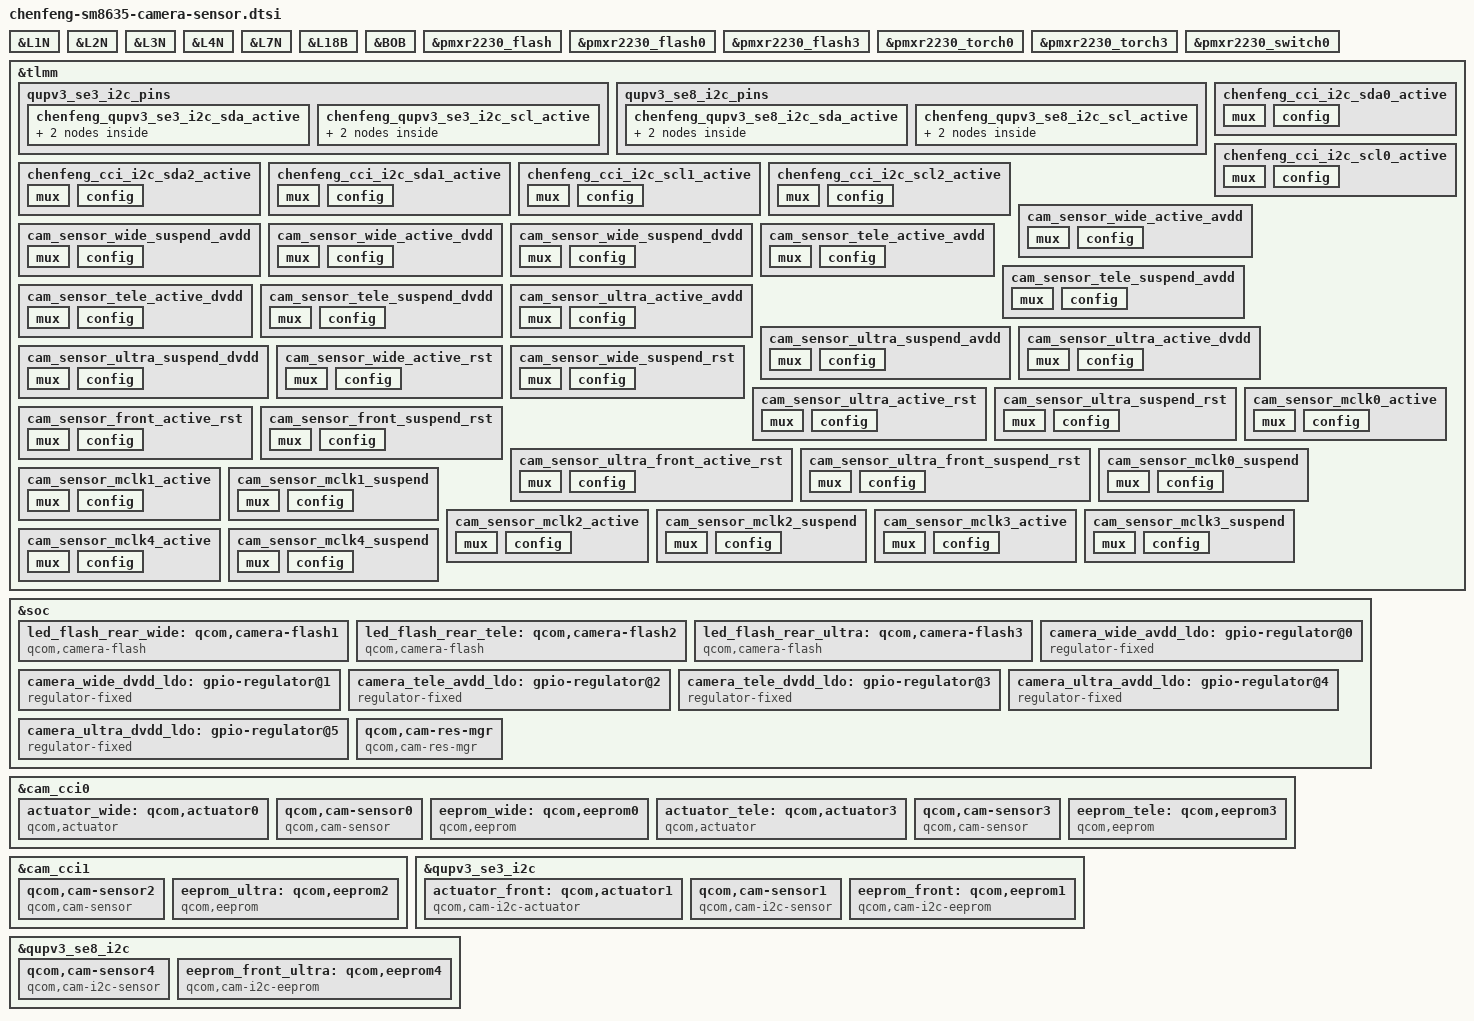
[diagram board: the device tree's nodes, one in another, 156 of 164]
#include <dt-bindings/msm-camera.h>

&L1N {
	regulator-min-microvolt = <1000000>;
	regulator-max-microvolt = <1000000>;
	qcom,init-voltage = <1000000>;
};

&L2N {
	regulator-min-microvolt = <1000000>;
	regulator-max-microvolt = <1000000>;
	qcom,init-voltage = <1000000>;
};

&L3N {
	regulator-min-microvolt = <2800000>;
	regulator-max-microvolt = <2800000>;
	qcom,init-voltage = <2800000>;
};

// CAM2X_AF_2P8
&L4N {
	regulator-min-microvolt = <2800000>;
	regulator-max-microvolt = <2800000>;
	qcom,init-voltage = <2800000>;
};

// CAMW_AFVDD_3P1
&L7N {
	regulator-min-microvolt = <3100000>;
	regulator-max-microvolt = <3100000>;
	qcom,init-voltage = <3100000>;
};

// CAMF_AFVDD_2P8
&L18B {
	regulator-min-microvolt = <2800000>;
	regulator-max-microvolt = <2800000>;
	qcom,init-voltage = <2800000>;
};

&BOB {
	regulator-min-microvolt = <3008000>;
	regulator-max-microvolt = <3960000>;
};

&pmxr2230_flash {
	status = "ok";
};

&pmxr2230_flash0 {
	qcom,max-current-ma = <400>;
	qcom,duration-ms = <300>;
	xiaomi,max-duration-ms = <300>;
};

&pmxr2230_flash3 {
	qcom,max-current-ma = <400>;
	qcom,duration-ms = <300>;
	xiaomi,max-duration-ms = <300>;
};

&pmxr2230_torch0{
	qcom,max-current-ma = <425>;
	xiaomi,currents-with-time = <425 150>;
	xiaomi,time-for-currents = <5000 0xFFFFFFFF>;  /* 0xFFFFFFFF means flash always on*/
};

&pmxr2230_torch3{
	qcom,max-current-ma = <425>;
	xiaomi,currents-with-time = <425 150>;
	xiaomi,time-for-currents = <5000 0xFFFFFFFF>;  /* 0xFFFFFFFF means flash always on*/
};

&pmxr2230_switch0 {
	qcom,led-mask = <9>; /* Channels 1 & 4 */
	qcom,symmetry-en;
};

&tlmm {

	qupv3_se3_i2c_pins: qupv3_se3_i2c_pins {
		chenfeng_qupv3_se3_i2c_sda_active: chenfeng_qupv3_se3_i2c_sda_active {
			mux {
				pins = "gpio12";
				function = "qup0_se3_l0";
			};

			config {
				pins = "gpio12";
				drive-strength = <2>;
				bias-disable; /* NO PULL */
				qcom,apps;
			};
		};

		chenfeng_qupv3_se3_i2c_scl_active: chenfeng_qupv3_se3_i2c_scl_active {
			mux {
				pins = "gpio13";
				function = "qup0_se3_l1";
			};

			config {
				pins = "gpio13";
				drive-strength = <2>;
				bias-disable; /* NO PULL */
				qcom,apps;
			};
		};
	};

	qupv3_se8_i2c_pins: qupv3_se8_i2c_pins {
		chenfeng_qupv3_se8_i2c_sda_active: chenfeng_qupv3_se8_i2c_sda_active {
			mux {
				pins = "gpio0";
				function = "qup1_se0_l0";
			};

			config {
				pins = "gpio0";
				drive-strength = <2>;
				bias-disable; /* NO PULL */
				qcom,apps;
			};
		};

		chenfeng_qupv3_se8_i2c_scl_active: chenfeng_qupv3_se8_i2c_scl_active {
			mux {
				pins = "gpio1";
				function = "qup1_se0_l1";
			};

			config {
				pins = "gpio1";
				drive-strength = <2>;
				bias-disable; /* NO PULL */
				qcom,apps;
			};
		};
	};

	chenfeng_cci_i2c_sda0_active: chenfeng_cci_i2c_sda0_active {
		mux {
			/* CLK, DATA */
			pins = "gpio70";
			function = "cci_i2c_sda0";
		};

		config {
			pins = "gpio70";
			bias-disable; /* NO PULL */
			drive-strength = <2>; /* 2 MA */
		};
	};

	chenfeng_cci_i2c_scl0_active: chenfeng_cci_i2c_scl0_active {
		mux {
			/* CLK, DATA */
			pins = "gpio71";
			function = "cci_i2c_scl0";
		};

		config {
			pins = "gpio71";
			bias-disable; /* NO PULL */
			drive-strength = <2>; /* 2 MA */
		};
	};

	chenfeng_cci_i2c_sda2_active: chenfeng_cci_i2c_sda2_active {
		mux {
			/* CLK, DATA */
			pins = "gpio74";
			function = "cci_i2c_sda2";
		};

		config {
			pins = "gpio74";
			bias-disable; /* NO PULL */
			drive-strength = <2>; /* 2 MA */
		};
	};

	chenfeng_cci_i2c_sda1_active: chenfeng_cci_i2c_sda1_active {
		mux {
			/* CLK, DATA */
			pins = "gpio72";
			function = "cci_i2c_sda1";
		};

		config {
			pins = "gpio72";
			bias-disable; /* NO PULL */
			drive-strength = <2>; /* 2 MA */
		};
	};

	chenfeng_cci_i2c_scl1_active: chenfeng_cci_i2c_scl1_active {
		mux {
			/* CLK, DATA */
			pins = "gpio73";
			function = "cci_i2c_scl1";
		};

		config {
			pins = "gpio73";
			bias-disable; /* NO PULL */
			drive-strength = <2>; /* 2 MA */
		};
	};

	chenfeng_cci_i2c_scl2_active: chenfeng_cci_i2c_scl2_active {
		mux {
			/* CLK, DATA */
			pins = "gpio75";
			function = "cci_i2c_scl2";
		};

		config {
			pins = "gpio75";
			bias-disable; /* NO PULL */
			drive-strength = <2>; /* 2 MA */
		};
	};


//WIDE avdd
	cam_sensor_wide_active_avdd: cam_sensor_wide_active_avdd {
		mux {
			pins = "gpio34";
			function = "gpio";
		};
		config {
			pins = "gpio34";
			bias-disable; /* No PULL */
			drive-strength = <2>; /* 2 MA */
		};
	};
	cam_sensor_wide_suspend_avdd: cam_sensor_wide_suspend_avdd {
		mux {
			pins = "gpio34";
			function = "gpio";
		};
		config {
			pins = "gpio34";
			bias-pull-down; /* PULL DOWN */
			drive-strength = <2>; /* 2 MA */
			output-low;
		};
	};

//WIDE dvdd
	cam_sensor_wide_active_dvdd: cam_sensor_wide_active_dvdd {
		mux {
			pins = "gpio116";
			function = "gpio";
		};
		config {
			pins = "gpio116";
			bias-disable; /* No PULL */
			drive-strength = <2>; /* 2 MA */
		};
	};
	cam_sensor_wide_suspend_dvdd: cam_sensor_wide_suspend_dvdd {
		mux {
			pins = "gpio116";
			function = "gpio";
		};
		config {
			pins = "gpio116";
			bias-pull-down; /* PULL DOWN */
			drive-strength = <2>; /* 2 MA */
			output-low;
		};
	};

//tele avdd
	cam_sensor_tele_active_avdd: cam_sensor_tele_active_avdd {
		mux {
			pins = "gpio149";
			function = "gpio";
		};

		config {
			pins = "gpio149";
			bias-disable; /* No PULL */
			drive-strength = <2>; /* 2 MA */
		};
	};
	cam_sensor_tele_suspend_avdd: cam_sensor_tele_suspend_avdd {
		mux {
			pins = "gpio149";
			function = "gpio";
		};

		config {
			pins = "gpio149";
			bias-pull-down; /* PULL DOWN */
			drive-strength = <2>; /* 2 MA */
			output-low;
		};
	};

//tele dvdd
	cam_sensor_tele_active_dvdd: cam_sensor_tele_active_dvdd {
		mux {
			pins = "gpio153";
			function = "gpio";
		};

		config {
			pins = "gpio153";
			bias-disable; /* No PULL */
			drive-strength = <2>; /* 2 MA */
		};
	};
	cam_sensor_tele_suspend_dvdd: cam_sensor_tele_suspend_dvdd {
		mux {
			pins = "gpio153";
			function = "gpio";
		};

		config {
			pins = "gpio153";
			bias-pull-down; /* PULL DOWN */
			drive-strength = <2>; /* 2 MA */
			output-low;
		};
	};

//ultra avdd
	cam_sensor_ultra_active_avdd: cam_sensor_ultra_active_avdd {
		mux {
			pins = "gpio123";
			function = "gpio";
		};
		config {
			pins = "gpio123";
			bias-disable; /* No PULL */
			drive-strength = <2>; /* 2 MA */
		};
	};
	cam_sensor_ultra_suspend_avdd: cam_sensor_ultra_suspend_avdd {
		mux {
			pins = "gpio123";
			function = "gpio";
		};
		config {
			pins = "gpio123";
			bias-pull-down; /* PULL DOWN */
			drive-strength = <2>; /* 2 MA */
			output-low;
		};
	};

//ultra dvdd
	cam_sensor_ultra_active_dvdd: cam_sensor_ultra_active_dvdd {
		mux {
			pins = "gpio124";
			function = "gpio";
		};
		config {
			pins = "gpio124";
			bias-disable; /* No PULL */
			drive-strength = <2>; /* 2 MA */
		};
	};
	cam_sensor_ultra_suspend_dvdd: cam_sensor_ultra_suspend_dvdd {
		mux {
			pins = "gpio124";
			function = "gpio";
		};
		config {
			pins = "gpio124";
			bias-pull-down; /* PULL DOWN */
			drive-strength = <2>; /* 2 MA */
			output-low;
		};
	};

// wide rst
	cam_sensor_wide_active_rst: cam_sensor_wide_active_rst {
		mux {
			pins = "gpio15";
			function = "gpio";
		};

		config {
			pins = "gpio15";
			bias-disable; /* No PULL */
			drive-strength = <2>; /* 2 MA */
		};
	};
	cam_sensor_wide_suspend_rst: cam_sensor_wide_suspend_rst {
		mux {
			pins = "gpio15";
			function = "gpio";
		};

		config {
			pins = "gpio15";
			bias-pull-down; /* PULL DOWN */
			drive-strength = <2>; /* 2 MA */
			output-low;
		};
	};

// ultra rst
	cam_sensor_ultra_active_rst: cam_sensor_ultra_active_rst {
		mux {
			pins = "gpio20";
			function = "gpio";
		};

		config {
			pins = "gpio20";
			bias-disable; /* No PULL */
			drive-strength = <2>; /* 2 MA */
		};
	};
	cam_sensor_ultra_suspend_rst: cam_sensor_ultra_suspend_rst {
		mux {
			pins = "gpio20";
			function = "gpio";
		};

		config {
			pins = "gpio20";
			bias-pull-down; /* PULL DOWN */
			drive-strength = <2>; /* 2 MA */
			output-low;
		};
	};

// front rst
	cam_sensor_front_active_rst: cam_sensor_front_active_rst {
		mux {
			pins = "gpio21";
			function = "gpio";
		};

		config {
			pins = "gpio21";
			bias-disable; /* No PULL */
			drive-strength = <2>; /* 2 MA */
		};
	};
	cam_sensor_front_suspend_rst: cam_sensor_front_suspend_rst {
		mux {
			pins = "gpio21";
			function = "gpio";
		};

		config {
			pins = "gpio21";
			bias-pull-down; /* PULL DOWN */
			drive-strength = <2>; /* 2 MA */
			output-low;
		};
	};

// ultra front rst
	cam_sensor_ultra_front_active_rst: cam_sensor_ultra_front_active_rst {
		mux {
			pins = "gpio3";
			function = "gpio";
		};
		config {
			pins = "gpio3";
			bias-disable; /* No PULL */
			drive-strength = <2>; /* 2 MA */
			qcom,apps;
		};
	};
	cam_sensor_ultra_front_suspend_rst: cam_sensor_ultra_front_suspend_rst {
		mux {
			pins = "gpio3";
			function = "gpio";
		};
		config {
			pins = "gpio3";
			bias-pull-down; /* PULL DOWN */
			drive-strength = <2>; /* 2 MA */
			output-low;
			qcom,remote;
		};
	};

// wide mclk
	cam_sensor_mclk0_active: cam_sensor_mclk0_active {
		/* MCLK0 */
		mux {
			pins = "gpio64";
			function = "cam_mclk";
		};

		config {
			pins = "gpio64";
			bias-disable; /* No PULL */
			drive-strength = <4>; /* 4 MA */
		};
	};

	cam_sensor_mclk0_suspend: cam_sensor_mclk0_suspend {
		/* MCLK0 */
		mux {
			pins = "gpio64";
			function = "cam_mclk";
		};

		config {
			pins = "gpio64";
			bias-pull-down; /* PULL DOWN */
			drive-strength = <4>; /* 4 MA */
		};
	};

// tele mclk
	cam_sensor_mclk1_active: cam_sensor_mclk1_active {
		/* MCLK1 */
		mux {
			pins = "gpio65";
			function = "cam_mclk";
		};

		config {
			pins = "gpio65";
			bias-disable; /* No PULL */
			drive-strength = <4>; /* 4 MA */
		};
	};

	cam_sensor_mclk1_suspend: cam_sensor_mclk1_suspend {
		/* MCLK1 */
		mux {
			pins = "gpio65";
			function = "cam_mclk";
		};

		config {
			pins = "gpio65";
			bias-pull-down; /* PULL DOWN */
			drive-strength = <4>; /* 4 MA */
		};
	};

// ultra mclk
	cam_sensor_mclk2_active: cam_sensor_mclk2_active {
		/* MCLK2 */
		mux {
			pins = "gpio66";
			function = "cam_mclk";
		};

		config {
			pins = "gpio66";
			bias-disable; /* No PULL */
			drive-strength = <4>; /* 4 MA */
		};
	};

	cam_sensor_mclk2_suspend: cam_sensor_mclk2_suspend {
		/* MCLK2 */
		mux {
			pins = "gpio66";
			function = "cam_mclk";
		};

		config {
			pins = "gpio66";
			bias-pull-down; /* PULL DOWN */
			drive-strength = <4>; /* 4 MA */
		};
	};

// front mclk
	cam_sensor_mclk3_active: cam_sensor_mclk3_active {
		/* MCLK3 */
		mux {
			pins = "gpio67";
			function = "cam_mclk";
		};

		config {
			pins = "gpio67";
			bias-disable; /* No PULL */
			drive-strength = <4>; /* 4 MA */
		};
	};

	cam_sensor_mclk3_suspend: cam_sensor_mclk3_suspend {
		/* MCLK3 */
		mux {
			pins = "gpio67";
			function = "cam_mclk";
		};

		config {
			pins = "gpio67";
			bias-pull-down; /* PULL DOWN */
			drive-strength = <4>; /* 4 MA */
		};
	};

// front ultra
	cam_sensor_mclk4_active: cam_sensor_mclk4_active {
		/* MCLK4 */
		mux {
			pins = "gpio68";
			function = "cam_aon_mclk4";
		};

		config {
			pins = "gpio68";
			bias-disable; /* No PULL */
			drive-strength = <4>; /* 4 MA */
		};
	};

	cam_sensor_mclk4_suspend: cam_sensor_mclk4_suspend {
		/* MCLK4 */
		mux {
			pins = "gpio68";
			function = "cam_mclk";
		};

		config {
			pins = "gpio68";
			bias-pull-down; /* PULL DOWN */
			drive-strength = <4>; /* 4 MA */
		};
	};

};

&soc {
	led_flash_rear_wide: qcom,camera-flash1 {
		cell-index = <1>;
		compatible = "qcom,camera-flash";
		flash-source = <&pmxr2230_flash0>;
		torch-source = <&pmxr2230_torch0>;
		switch-source = <&pmxr2230_switch0>;
		status = "ok";
	};

	led_flash_rear_tele: qcom,camera-flash2 {
		cell-index = <2>;
		compatible = "qcom,camera-flash";
		flash-source = <&pmxr2230_flash0>;
		torch-source = <&pmxr2230_torch0>;
		switch-source = <&pmxr2230_switch0>;
		status = "ok";
	};

	led_flash_rear_ultra: qcom,camera-flash3 {
		cell-index = <3>;
		compatible = "qcom,camera-flash";
		flash-source = <&pmxr2230_flash0>;
		torch-source = <&pmxr2230_torch0>;
		switch-source = <&pmxr2230_switch0>;
		status = "ok";
	};

	camera_wide_avdd_ldo: gpio-regulator@0 {
		compatible = "regulator-fixed";
		reg = <0x00 0x00>;
		regulator-name = "camera_wide_avdd_ldo";
		regulator-min-microvolt = <2800000>;
		regulator-max-microvolt = <2800000>;
		regulator-enable-ramp-delay = <100>;
		enable-active-high;
		gpio = <&tlmm 34 0>;
		pinctrl-names = "wide_avdd_active", "wide_avdd_suspend";
		pinctrl-0 = <&cam_sensor_wide_active_avdd
					 &cam_sensor_wide_suspend_avdd>;
	};

	camera_wide_dvdd_ldo: gpio-regulator@1 {
		compatible = "regulator-fixed";
		reg = <0x01 0x00>;
		regulator-name = "camera_wide_dvdd_ldo";
		regulator-min-microvolt = <1100000>;
		regulator-max-microvolt = <1100000>;
		regulator-enable-ramp-delay = <100>;
		enable-active-high;
		gpio = <&tlmm 116 0>;
		pinctrl-names = "wide_dvdd_active", "wide_dvdd_suspend";
		pinctrl-0 = <&cam_sensor_wide_active_dvdd
					 &cam_sensor_wide_suspend_dvdd>;
	};

	camera_tele_avdd_ldo: gpio-regulator@2 {
		compatible = "regulator-fixed";
		reg = <0x02 0x00>;
		regulator-name = "camera_tele_avdd_ldo";
		regulator-min-microvolt = <2800000>;
		regulator-max-microvolt = <2800000>;
		regulator-enable-ramp-delay = <100>;
		enable-active-high;
		gpio = <&tlmm 149 0>;
		pinctrl-names = "tele_avdd_active", "tele_avdd_suspend";
		pinctrl-0 = <&cam_sensor_tele_active_avdd
					&cam_sensor_tele_suspend_avdd>;
	};

	camera_tele_dvdd_ldo: gpio-regulator@3 {
		compatible = "regulator-fixed";
		reg = <0x03 0x00>;
		regulator-name = "camera_tele_dvdd_ldo";
		regulator-min-microvolt = <1050000>;
		regulator-max-microvolt = <1050000>;
		regulator-enable-ramp-delay = <100>;
		enable-active-high;
		gpio = <&tlmm 153 0>;
		pinctrl-names = "tele_dvdd_active", "tele_dvdd_suspend";
		pinctrl-0 = <&cam_sensor_tele_active_dvdd
					&cam_sensor_tele_suspend_dvdd>;
	};

	camera_ultra_avdd_ldo: gpio-regulator@4 {
		compatible = "regulator-fixed";
		reg = <0x04 0x00>;
		regulator-name = "camera_ultra_avdd_ldo";
		regulator-min-microvolt = <2800000>;
		regulator-max-microvolt = <2800000>;
		regulator-enable-ramp-delay = <100>;
		enable-active-high;
		gpio = <&tlmm 123 0>;
		pinctrl-names = "ultra_avdd_active", "ultra_avdd_suspend";
		pinctrl-0 = <&cam_sensor_ultra_active_avdd
					&cam_sensor_ultra_suspend_avdd>;
	};

	camera_ultra_dvdd_ldo: gpio-regulator@5 {
		compatible = "regulator-fixed";
		reg = <0x05 0x00>;
		regulator-name = "camera_ultra_dvdd_ldo";
		regulator-min-microvolt = <1200000>;
		regulator-max-microvolt = <1200000>;
		regulator-enable-ramp-delay = <100>;
		enable-active-high;
		gpio = <&tlmm 124 0>;
		pinctrl-names = "ultra_dvdd_active", "ultra_dvdd_suspend";
		pinctrl-0 = <&cam_sensor_ultra_active_dvdd
					&cam_sensor_ultra_suspend_dvdd>;
	};

	qcom,cam-res-mgr {
		compatible = "qcom,cam-res-mgr";
		gpios-shared-pinctrl = <400 354>;
		shared-pctrl-gpio-names = "cam_front", "cam_front";
		pinctrl-names = "cam_front_active", "cam_front_suspend";
		pinctrl-0 = <&cam_sensor_mclk3_active
			&cam_sensor_front_active_rst>;
		pinctrl-1 = <&cam_sensor_mclk3_suspend
			&cam_sensor_front_suspend_rst>;
		status = "ok";
	};

};

&cam_cci0 {
	//Remove I2C gpio pull-up setting for resolve voltage step
	pinctrl-0 = <&chenfeng_cci_i2c_scl0_active &chenfeng_cci_i2c_sda0_active>;
	pinctrl-2 = <&chenfeng_cci_i2c_scl1_active &chenfeng_cci_i2c_sda1_active>;

	// wide actuator
	actuator_wide: qcom,actuator0 {
		cell-index = <0>;
		compatible = "qcom,actuator";
		cci-master = <CCI_MASTER_0>;
		cam_vana-supply = <&camera_wide_avdd_ldo>;
		cam_vio-supply = <&L23B>;
		cam_vdig-supply = <&camera_wide_dvdd_ldo>;
		cam_clk-supply = <&cam_cc_titan_top_gdsc>;
		cam_vaf-supply = <&L7N>;
		regulator-names = "cam_vana", "cam_vio",
			"cam_vdig", "cam_clk", "cam_vaf";
		rgltr-cntrl-support;
		rgltr-min-voltage = <2800000 1800000 1100000 0 3100000>;
		rgltr-max-voltage = <2800000 1800000 1100000 0 3100000>;
		rgltr-load-current = <102000 1000 796500 0 150000>;
	};

	//wide sensor
	qcom,cam-sensor0 {
		cell-index = <0>;
		compatible = "qcom,cam-sensor";
		csiphy-sd-index = <0>;
		actuator-src = <&actuator_wide>;
		led-flash-src = <&led_flash_rear_wide>;
		eeprom-src = <&eeprom_wide>;
		sensor-position-roll = <90>;
		sensor-position-pitch = <0>;
		sensor-position-yaw = <180>;
		cam_vana-supply = <&camera_wide_avdd_ldo>; //ok
		cam_vio-supply = <&L23B>;
		cam_bob-supply = <&BOB>;
		cam_vdig-supply = <&camera_wide_dvdd_ldo>;
		cam_clk-supply = <&cam_cc_titan_top_gdsc>; //ok
		regulator-names = "cam_vana", "cam_vio",
			"cam_vdig", "cam_clk", "cam_bob";
		rgltr-cntrl-support;
		rgltr-min-voltage = <2800000 1800000 1100000 0 3008000>;
		rgltr-max-voltage = <2800000 1800000 1100000 0 3960000>;
		rgltr-load-current = <102000 1000 796500 0 2000000>;
		gpio-no-mux = <0>;
		// use-shared-clk;
		pinctrl-names = "cam_default", "cam_suspend";
		pinctrl-0 = <&cam_sensor_mclk0_active
			&cam_sensor_wide_active_rst>;
		pinctrl-1 = <&cam_sensor_mclk0_suspend
			&cam_sensor_wide_suspend_rst>;
		gpios = <&tlmm 64 0>, <&tlmm 15 0>;
		gpio-reset = <1>;
		gpio-req-tbl-num = <0 1>;
		gpio-req-tbl-flags = <1 0>;
		gpio-req-tbl-label = "CAMIF_MCLK0", "CAM_RESET_WIDE";
		cci-master = <CCI_MASTER_0>;
		clocks = <&camcc CAM_CC_MCLK0_CLK>;
		clock-names = "cam_clk";
		clock-cntl-level = "nominal";
		clock-rates = <19200000>;
		status = "ok";
	};

	//wide eeprom
	eeprom_wide:qcom,eeprom0 {
		cell-index = <0>;
		compatible = "qcom,eeprom";
		cam_vana-supply = <&camera_wide_avdd_ldo>;
		cam_vio-supply = <&L23B>;
		cam_vdig-supply = <&camera_wide_dvdd_ldo>;
		cam_clk-supply = <&cam_cc_titan_top_gdsc>;
		regulator-names = "cam_vana", "cam_vio",
			"cam_vdig", "cam_clk";
		rgltr-cntrl-support;
		rgltr-min-voltage = <2800000 1800000 1100000 0>;
		rgltr-max-voltage = <2800000 1800000 1100000 0>;
		rgltr-load-current = <102000 1000 796500 0>;
		gpio-no-mux = <0>;
		// use-shared-clk;
		pinctrl-names = "cam_default", "cam_suspend";
		pinctrl-0 = <&cam_sensor_mclk0_active
			&cam_sensor_wide_active_rst>;
		pinctrl-1 = <&cam_sensor_mclk0_suspend
			&cam_sensor_wide_suspend_rst>;
		gpios = <&tlmm 64 0>, <&tlmm 15 0>;
		gpio-reset = <1>;
		gpio-req-tbl-num = <0 1>;
		gpio-req-tbl-flags = <1 0>;
		gpio-req-tbl-label = "CAMIF_MCLK0", "CAM_RESET_WIDE";
		cci-master = <CCI_MASTER_0>;
		clocks = <&camcc CAM_CC_MCLK0_CLK>;
		clock-names = "cam_clk";
		clock-cntl-level = "nominal";
		clock-rates = <19200000>;
		status = "ok";
	};

	// tele actuator
	actuator_tele: qcom,actuator3 {
		cell-index = <3>;
		compatible = "qcom,actuator";
		cci-master = <CCI_MASTER_1>;
		cam_vana-supply = <&camera_tele_avdd_ldo>;
		cam_vio-supply = <&L23B>;
		cam_vdig-supply = <&camera_tele_dvdd_ldo>;
		cam_clk-supply = <&cam_cc_titan_top_gdsc>;
		cam_vaf-supply = <&L4N>;
		regulator-names = "cam_vana", "cam_vio", "cam_vdig",
			"cam_clk", "cam_vaf";
		rgltr-cntrl-support;
		rgltr-min-voltage = <2800000 1800000 1050000 0 2800000>;
		rgltr-max-voltage = <2800000 1800000 1050000 0 2800000>;
		rgltr-load-current = <57900 2500 216000 0 73000>;
	};

	// tele sensor
	qcom,cam-sensor3 {
		cell-index = <3>;
		compatible = "qcom,cam-sensor";
		csiphy-sd-index = <1>;
		actuator-src = <&actuator_tele>;
		led-flash-src = <&led_flash_rear_tele>;
		eeprom-src = <&eeprom_tele>;
		sensor-position-roll = <90>;
		sensor-position-pitch = <0>;
		sensor-position-yaw = <180>;
		cam_vana-supply = <&camera_tele_avdd_ldo>;
		cam_vio-supply = <&L23B>;
		cam_bob-supply = <&BOB>;
		cam_vdig-supply = <&camera_tele_dvdd_ldo>;
		cam_clk-supply = <&cam_cc_titan_top_gdsc>;
		regulator-names = "cam_vana", "cam_vio", "cam_vdig",
			"cam_clk", "cam_bob";
		rgltr-cntrl-support;
		rgltr-min-voltage = <2800000 1800000 1050000 0 3008000>;
		rgltr-max-voltage = <2800000 1800000 1050000 0 3960000>;
		rgltr-load-current = <57900 2500 216000 0 2000000>;
		gpio-no-mux = <0>;
		// use-shared-clk;
		pinctrl-names = "cam_default", "cam_suspend";
		pinctrl-0 = <&cam_sensor_mclk1_active
			&cam_sensor_active_rst1>;
		pinctrl-1 = <&cam_sensor_mclk1_suspend
			&cam_sensor_suspend_rst1>;
		gpios = <&tlmm 65 0>, <&tlmm 14 0>;
		gpio-reset = <1>;
		gpio-req-tbl-num = <0 1>;
		gpio-req-tbl-flags = <1 0>;
		gpio-req-tbl-label = "CAMIF_MCLK1", "CAM_RESET1";
		cci-master = <CCI_MASTER_1>;
		clocks = <&camcc CAM_CC_MCLK1_CLK>;
		clock-names = "cam_clk";
		clock-cntl-level = "nominal";
		clock-rates = <19200000>;
		status = "ok";
	};

	eeprom_tele:qcom,eeprom3 {
		cell-index = <3>;
		compatible = "qcom,eeprom";
		cam_vana-supply = <&camera_tele_avdd_ldo>;
		cam_vio-supply = <&L23B>;
		cam_vdig-supply = <&camera_tele_dvdd_ldo>;
		cam_clk-supply = <&cam_cc_titan_top_gdsc>;
		regulator-names = "cam_vana", "cam_vio", "cam_vdig",
			"cam_clk";
		rgltr-cntrl-support;
		rgltr-min-voltage = <2800000 1800000 1050000 0>;
		rgltr-max-voltage = <2800000 1800000 1050000 0>;
		rgltr-load-current = <57900 2500 216000 0>;
		gpio-no-mux = <0>;
		// use-shared-clk;
		pinctrl-names = "cam_default", "cam_suspend";
		pinctrl-0 = <&cam_sensor_mclk1_active
			&cam_sensor_active_rst1>;
		pinctrl-1 = <&cam_sensor_mclk1_suspend
			&cam_sensor_suspend_rst1>;
		gpios = <&tlmm 65 0>, <&tlmm 14 0>;
		gpio-reset = <1>;
		gpio-req-tbl-num = <0 1>;
		gpio-req-tbl-flags = <1 0>;
		gpio-req-tbl-label = "CAMIF_MCLK1", "CAM_RESET1";
		cci-master = <CCI_MASTER_1>;
		clocks = <&camcc CAM_CC_MCLK1_CLK>;
		clock-names = "cam_clk";
		clock-cntl-level = "nominal";
		clock-rates = <19200000>;
		status = "ok";
	};

};

&cam_cci1 {
	//Remove I2C gpio pull-up setting for resolve voltage step
	pinctrl-0 = <&chenfeng_cci_i2c_scl2_active &chenfeng_cci_i2c_sda2_active>;

	//ultra sensor
	qcom,cam-sensor2 {
		cell-index = <2>;
		compatible = "qcom,cam-sensor";
		csiphy-sd-index = <2>;
		led-flash-src = <&led_flash_rear_ultra>;
		eeprom-src = <&eeprom_ultra>;
		sensor-position-roll = <90>;
		sensor-position-pitch = <0>;
		sensor-position-yaw = <180>;
		cam_vana-supply = <&camera_ultra_avdd_ldo>;
		cam_vio-supply = <&L23B>;
		cam_bob-supply = <&BOB>;
		cam_vdig-supply = <&camera_ultra_dvdd_ldo>;
		cam_clk-supply = <&cam_cc_titan_top_gdsc>;
		regulator-names = "cam_vana", "cam_vio", "cam_vdig", "cam_clk", "cam_bob";
		rgltr-cntrl-support;
		rgltr-min-voltage = <2800000 1800000 1200000 0 3008000>;
		rgltr-max-voltage = <2800000 1800000 1200000 0 3960000>;
		rgltr-load-current = <57900 300 216200 0 2000000>;
		gpio-no-mux = <0>;
		pinctrl-names = "cam_default", "cam_suspend";
		pinctrl-0 = <&cam_sensor_mclk2_active
			&cam_sensor_ultra_active_rst>;
		pinctrl-1 = <&cam_sensor_mclk2_suspend
			&cam_sensor_ultra_suspend_rst>;
		gpios = <&tlmm 66 0>, <&tlmm 20 0>;
		gpio-reset = <1>;
		gpio-req-tbl-num = <0 1>;
		gpio-req-tbl-flags = <1 0>;
		gpio-req-tbl-label = "CAMIF_MCLK2", "CAM_RESET2";
		cci-master = <CCI_MASTER_0>;
		clocks = <&camcc CAM_CC_MCLK2_CLK>;
		clock-names = "cam_clk";
		clock-cntl-level = "nominal";
		clock-rates = <19200000>;
		status = "ok";
	};

	//ultra eeprom
	eeprom_ultra: qcom,eeprom2 {
		cell-index = <2>;
		compatible = "qcom,eeprom";
		cam_vana-supply = <&camera_ultra_avdd_ldo>;
		cam_vio-supply = <&L23B>;
		cam_vdig-supply = <&camera_ultra_dvdd_ldo>;
		cam_clk-supply = <&cam_cc_titan_top_gdsc>;
		regulator-names = "cam_vana", "cam_vio", "cam_vdig", "cam_clk";
		rgltr-cntrl-support;
		rgltr-min-voltage = <2800000 1800000 1200000 0>;
		rgltr-max-voltage = <2800000 1800000 1200000 0>;
		rgltr-load-current = <57900 300 216200 0>;
		gpio-no-mux = <0>;
		pinctrl-names = "cam_default", "cam_suspend";
		pinctrl-0 = <&cam_sensor_mclk2_active
			&cam_sensor_ultra_active_rst>;
		pinctrl-1 = <&cam_sensor_mclk2_suspend
			&cam_sensor_ultra_suspend_rst>;
		gpios = <&tlmm 66 0>, <&tlmm 20 0>;
		gpio-reset = <1>;
		gpio-req-tbl-num = <0 1>;
		gpio-req-tbl-flags = <1 0>;
		gpio-req-tbl-label = "CAMIF_MCLK2", "CAM_RESET2";
		cci-master = <CCI_MASTER_0>;
		clocks = <&camcc CAM_CC_MCLK2_CLK>;
		clock-names = "cam_clk";
		clock-cntl-level = "nominal";
		clock-rates = <19200000>;
		status = "ok";
	};
};

&qupv3_se3_i2c {
	status = "ok";
	qcom,clk-freq-out = <1000000>;
	qcom,pm-ctrl-client;

	//Remove I2C gpio pull-up setting for resolve voltage step
	pinctrl-0 = <&chenfeng_qupv3_se3_i2c_sda_active>, <&chenfeng_qupv3_se3_i2c_scl_active>;

	// front actuator
	actuator_front: qcom,actuator1 {
		cell-index = <1>;
		reg = <0x0C>;
		compatible = "qcom,cam-i2c-actuator";
		cam_vana-supply = <&L3N>;
		cam_vio-supply = <&L23B>;
		cam_vdig-supply = <&L1N>;
		cam_clk-supply = <&cam_cc_titan_top_gdsc>;
		cam_vaf-supply = <&L18B>;
		regulator-names = "cam_vana", "cam_vio",
			"cam_vdig", "cam_clk", "cam_vaf";
		rgltr-cntrl-support;
		rgltr-min-voltage = <2800000 1800000 1000000 0 2800000>;
		rgltr-max-voltage = <2800000 1800000 1000000 0 2800000>;
		rgltr-load-current = <57900 300 216200 0 73000>;
		gpio-no-mux = <0>;
		gpio-reset = <1>;
		gpio-req-tbl-num = <0 1>;
		gpio-req-tbl-flags = <1 0>;
		gpio-req-tbl-label = "CAMIF_MCLK3", "CAM_RESET1";
		clocks = <&camcc CAM_CC_MCLK3_CLK>;
		clock-names = "cam_clk";
		clock-cntl-level = "nominal";
		clock-rates = <19200000>;
		status = "ok";
	};

	// front sensor
	qcom,cam-sensor1 {
		cell-index = <1>;
		reg = <0x10>;
		compatible = "qcom,cam-i2c-sensor";
		csiphy-sd-index = <3>;
		actuator-src = <&actuator_front>;
		sensor-position-roll = <270>;
		sensor-position-pitch = <0>;
		sensor-position-yaw = <0>;
		eeprom-src = <&eeprom_front>;
		cam_vana-supply = <&L3N>;
		cam_vio-supply = <&L23B>;
		cam_vdig-supply = <&L1N>;
		cam_bob-supply = <&BOB>;
		cam_clk-supply = <&cam_cc_titan_top_gdsc>;
		regulator-names = "cam_vana", "cam_vio",
			"cam_vdig", "cam_clk", "cam_bob";
		rgltr-cntrl-support;
		rgltr-min-voltage = <2800000 1800000 1000000 0 3008000>;
		rgltr-max-voltage = <2800000 1800000 1000000 0 3960000>;
		rgltr-load-current = <57900 300 216200 0 2000000>;
		gpio-no-mux = <0>;
		use-shared-clk;
		// pinctrl-names = "cam_default", "cam_suspend";
		// pinctrl-0 = <&cam_sensor_mclk3_active
		// 	&cam_sensor_front_active_rst>;
		// pinctrl-1 = <&cam_sensor_mclk3_suspend
		// 	&cam_sensor_front_suspend_rst>;
		gpios = <&tlmm 67 0>, <&tlmm 21 0>;
		gpio-reset = <1>;
		gpio-req-tbl-num = <0 1>;
		gpio-req-tbl-flags = <1 0>;
		gpio-req-tbl-label = "CAMIF_MCLK3", "CAM_RESET1";
		cci-master = <CCI_MASTER_1>;
		clocks = <&camcc CAM_CC_MCLK3_CLK>;
		clock-names = "cam_clk";
		clock-cntl-level = "nominal";
		clock-rates = <19200000>;
		status = "ok";
	};

	//front eeprom
	eeprom_front: qcom,eeprom1 {
		cell-index = <1>;
		reg = <0x51>;
		compatible = "qcom,cam-i2c-eeprom";
		cam_vana-supply = <&L3N>;
		cam_vio-supply = <&L23B>;
		cam_vdig-supply = <&L1N>;
		cam_clk-supply = <&cam_cc_titan_top_gdsc>;
		regulator-names = "cam_vana", "cam_vio",
			"cam_vdig", "cam_clk";
		rgltr-cntrl-support;
		rgltr-min-voltage = <2800000 1800000 1000000 0>;
		rgltr-max-voltage = <2800000 1800000 1000000 0>;
		rgltr-load-current = <57900 300 216200 0>;
		gpio-no-mux = <0>;
		use-shared-clk;
		// pinctrl-names = "cam_default", "cam_suspend";
		// pinctrl-0 = <&cam_sensor_mclk3_active
		// 	&cam_sensor_front_active_rst>;
		// pinctrl-1 = <&cam_sensor_mclk3_suspend
		// 	&cam_sensor_front_suspend_rst>;
		gpios = <&tlmm 67 0>, <&tlmm 21 0>;
		gpio-reset = <1>;
		gpio-req-tbl-num = <0 1>;
		gpio-req-tbl-flags = <1 0>;
		gpio-req-tbl-label = "CAMIF_MCLK3", "CAM_RESET1";
		clocks = <&camcc CAM_CC_MCLK3_CLK>;
		clock-names = "cam_clk";
		clock-cntl-level = "nominal";
		clock-rates = <19200000>;
		status = "ok";
	};

};

&qupv3_se8_i2c {
	status = "ok";
	qcom,clk-freq-out = <1000000>;
	qcom,pm-ctrl-client;

	//Remove I2C gpio pull-up setting for resolve voltage step
	pinctrl-0 = <&chenfeng_qupv3_se8_i2c_sda_active>, <&chenfeng_qupv3_se8_i2c_scl_active>;

	// ultra front sensor
	qcom,cam-sensor4 {
		cell-index = <4>;
		reg = <0x10>;
		compatible = "qcom,cam-i2c-sensor";
		csiphy-sd-index = <4>;
		sensor-position-roll = <270>;
		sensor-position-pitch = <0>;
		sensor-position-yaw = <0>;
		aon-camera-id = <AON_CAM1>;
		eeprom-src = <&eeprom_front_ultra>;
		cam_vana-supply = <&L6N>;
		cam_vio-supply = <&L5N>;
		cam_vdig-supply = <&L2N>;
		cam_bob-supply = <&BOB>;
		cam_clk-supply = <&cam_cc_titan_top_gdsc>;
		regulator-names = "cam_vana", "cam_vio",
			"cam_vdig", "cam_clk", "cam_bob";
		rgltr-cntrl-support;
		rgltr-min-voltage = <2800000 1800000 1000000 0 3008000>;
		rgltr-max-voltage = <2800000 1800000 1000000 0 3960000>;
		rgltr-load-current = <43500 300 93000 0 2000000>;
		gpio-no-mux = <0>;
		pinctrl-names = "cam_default", "cam_suspend";
		pinctrl-0 = <&cam_sensor_mclk4_active
			&cam_sensor_ultra_front_active_rst>;
		pinctrl-1 = <&cam_sensor_mclk4_suspend
			&cam_sensor_ultra_front_suspend_rst>;
		gpios = <&tlmm 68 0>, <&tlmm 3 0>;
		gpio-reset = <1>;
		gpio-req-tbl-num = <0 1>;
		gpio-req-tbl-flags = <1 0>;
		gpio-req-tbl-label = "CAMIF_MCLK4", "CAM_RESET4";
		clocks = <&camcc CAM_CC_MCLK4_CLK>;
		clock-names = "cam_clk";
		clock-cntl-level = "nominal";
		clock-rates = <19200000>;
		status = "ok";
	};

	//front ultra eeprom
	eeprom_front_ultra: qcom,eeprom4 {
		cell-index = <4>;
		reg = <0x51>;
		compatible = "qcom,cam-i2c-eeprom";
		cam_vana-supply = <&L6N>;
		cam_vio-supply = <&L5N>;
		cam_vdig-supply = <&L2N>;
		cam_clk-supply = <&cam_cc_titan_top_gdsc>;
		regulator-names = "cam_vana", "cam_vio",
			"cam_vdig", "cam_clk";
		rgltr-cntrl-support;
		rgltr-min-voltage = <2800000 1800000 1000000 0>;
		rgltr-max-voltage = <2800000 1800000 1000000 0>;
		rgltr-load-current = <43500 300 93000 0>;
		gpio-no-mux = <0>;
		pinctrl-names = "cam_default", "cam_suspend";
		pinctrl-0 = <&cam_sensor_mclk4_active
			&cam_sensor_ultra_front_active_rst>;
		pinctrl-1 = <&cam_sensor_mclk4_suspend
			&cam_sensor_ultra_front_suspend_rst>;
		gpios = <&tlmm 68 0>, <&tlmm 3 0>;
		gpio-reset = <1>;
		gpio-req-tbl-num = <0 1>;
		gpio-req-tbl-flags = <1 0>;
		gpio-req-tbl-label = "CAMIF_MCLK4", "CAM_RESET4";
		clocks = <&camcc CAM_CC_MCLK4_CLK>;
		clock-names = "cam_clk";
		clock-cntl-level = "nominal";
		clock-rates = <19200000>;
		status = "ok";
	};
};
